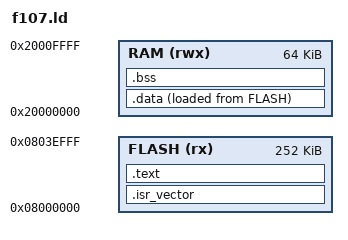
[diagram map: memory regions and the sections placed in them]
/* STM32F107VC: 256 KB flash, 64 KB RAM. */
ENTRY(Reset_Handler)

MEMORY
{
    FLASH (rx)  : ORIGIN = 0x08000000, LENGTH = 252K /* last 4 KB: config pages A/B */
    RAM   (rwx) : ORIGIN = 0x20000000, LENGTH = 64K
}

_estack = ORIGIN(RAM) + LENGTH(RAM);

SECTIONS
{
    .isr_vector : {
        KEEP(*(.isr_vector))
    } > FLASH

    .text : {
        *(.text*)
        *(.rodata*)
    } > FLASH

    _sidata = LOADADDR(.data);

    .data : {
        _sdata = .;
        *(.data*)
        _edata = .;
    } > RAM AT > FLASH

    .bss : {
        _sbss = .;
        *(.bss*)
        *(COMMON)
        _ebss = .;
    } > RAM

    /* newlib's sbrk (pulled from -specs=nosys) expects these. */
    end = .;
    _end = .;
    __bss_start__ = _sbss;
    __bss_end__ = _ebss;
}
